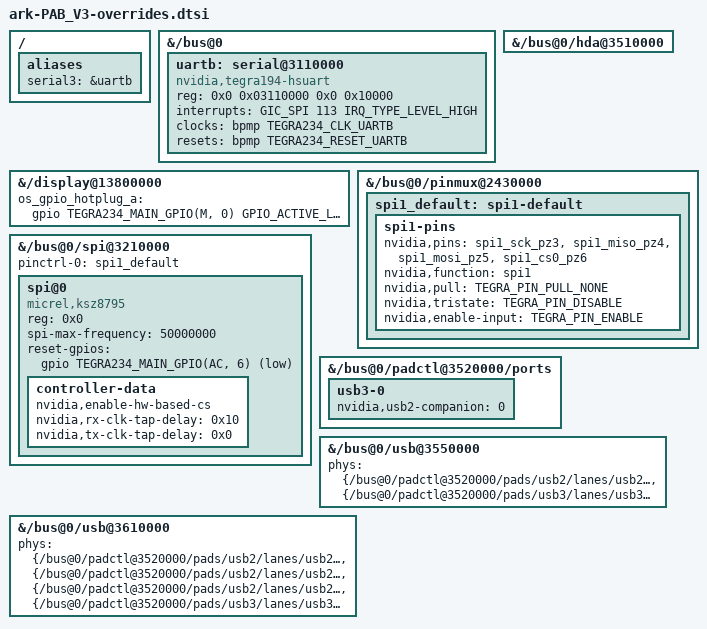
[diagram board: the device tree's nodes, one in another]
// SPDX-License-Identifier: GPL-2.0
/*
 * ARK PAB_V3 carrier device-tree delta.
 *
 * build.sh appends an #include of this file to the stock
 * tegra234-p3768-0000+p3767-xxxx-nv-common.dtsi, so it is layered last over the
 * pristine BSP tree. Only ARK's delta lives here; everything else tracks the BSP.
 * Per-SKU model strings are stamped separately from products/PAB_V3/dtb_models.env.
 */

#include <dt-bindings/pinctrl/pinctrl-tegra.h>

/* HDMI display: re-assigns display@13800000's nvidia,dcb-image with the HDMI blob. */
#include "tegra234-dcb-p3737-0000-p3701-0000-hdmi.dtsi"

/ {
	aliases {
		serial3 = &uartb;
	};
};

/* UARTB is wired on the carrier but undefined by the stock SoC dtsi. Declared as an
 * hsuart (not the tegra20-uart/8250 base) so it enumerates as /dev/ttyTHS*, like the
 * other Tegra UARTs; PIO mode (add dmas/dma-names for DMA). */
&{/bus@0} {
	uartb: serial@3110000 {
		compatible = "nvidia,tegra194-hsuart";
		reg = <0x0 0x03110000 0x0 0x10000>;
		interrupts = <GIC_SPI 113 IRQ_TYPE_LEVEL_HIGH>;
		clocks = <&bpmp TEGRA234_CLK_UARTB>;
		resets = <&bpmp TEGRA234_RESET_UARTB>;
		reset-names = "serial";
		status = "okay";
	};
};

/* HD-Audio is used on the carrier. */
&{/bus@0/hda@3510000} {
	status = "okay";
};

/* Hotplug detect line is active-low on the PAB_V3 carrier. */
&{/display@13800000} {
	os_gpio_hotplug_a = <&gpio TEGRA234_MAIN_GPIO(M, 0) GPIO_ACTIVE_LOW>;
};

/* SPI1 pin group for the KSZ8795 management interface. */
&{/bus@0/pinmux@2430000} {
	spi1_default: spi1-default {
		spi1-pins {
			nvidia,pins = "spi1_sck_pz3", "spi1_miso_pz4",
				      "spi1_mosi_pz5", "spi1_cs0_pz6";
			nvidia,function = "spi1";
			nvidia,pull = <TEGRA_PIN_PULL_NONE>;
			nvidia,tristate = <TEGRA_PIN_DISABLE>;
			nvidia,enable-input = <TEGRA_PIN_ENABLE>;
		};
	};
};

/* SPI1: KSZ8795CLX ethernet switch management interface on CS0. */
&{/bus@0/spi@3210000} {
	status = "okay";
	pinctrl-names = "default";
	pinctrl-0 = <&spi1_default>;

	spi@0 {
		compatible = "micrel,ksz8795";
		reg = <0x0>;
		spi-max-frequency = <50000000>;
		reset-gpios = <&gpio TEGRA234_MAIN_GPIO(AC, 6) GPIO_ACTIVE_LOW>;
		controller-data {
			nvidia,enable-hw-based-cs;
			nvidia,rx-clk-tap-delay = <0x10>;
			nvidia,tx-clk-tap-delay = <0x0>;
		};
	};
};

/* Carrier USB port mapping: only usb3-0 (USB-C) is brought out. */
&{/bus@0/padctl@3520000/ports} {
	/delete-node/ usb3-1;
	usb3-0 { nvidia,usb2-companion = <0>; };
};

&{/bus@0/usb@3550000} {
	phys = <&{/bus@0/padctl@3520000/pads/usb2/lanes/usb2-0}>,
	       <&{/bus@0/padctl@3520000/pads/usb3/lanes/usb3-0}>;
	phy-names = "usb2-0", "usb3-0";
};

&{/bus@0/usb@3610000} {
	phys = <&{/bus@0/padctl@3520000/pads/usb2/lanes/usb2-0}>,
	       <&{/bus@0/padctl@3520000/pads/usb2/lanes/usb2-1}>,
	       <&{/bus@0/padctl@3520000/pads/usb2/lanes/usb2-2}>,
	       <&{/bus@0/padctl@3520000/pads/usb3/lanes/usb3-0}>;
	phy-names = "usb2-0", "usb2-1", "usb2-2", "usb3-0";
};
